# STM32H723xx register map
File version: 1.0
Registers are 32-bit, read-write, reset 0x0 unless marked. A register's access mark holds for its fields unless they carry their own. Offsets are from the block's base; [hi:lo] are bit positions; {n}, {i} and the like mark numbered series; 'fields as' and 'values as' point back to an identical list.

## FMC_Bank1E_R — Flexible Memory Controller Bank1E
Base 0x52004104
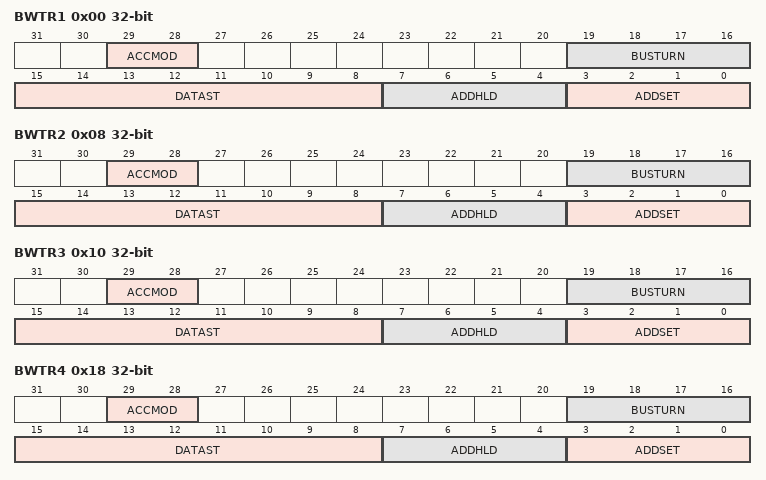
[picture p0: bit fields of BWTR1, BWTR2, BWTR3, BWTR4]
0x00 BWTR1 — NOR/PSRAM write timing registers
  [29:28] ACCMOD — ACCMOD[1:0] bits (Access mode)
  [19:16] BUSTURN — BUSTURN[3:0] bits (Bus turnaround phase duration)
  [15:8] DATAST — DATAST [3:0] bits (Data-phase duration)
  [7:4] ADDHLD — ADDHLD[3:0] bits (Address-hold phase duration)
  [3:0] ADDSET — ADDSET[3:0] bits (Address setup phase duration)
0x08 BWTR2 — NOR/PSRAM write timing registers
  fields as BWTR1
0x10 BWTR3 — NOR/PSRAM write timing registers
  fields as BWTR1
0x18 BWTR4 — NOR/PSRAM write timing registers
  fields as BWTR1

## FMC_Bank5_6_R — Flexible Memory Controller Bank5 and 6
Base 0x52004140
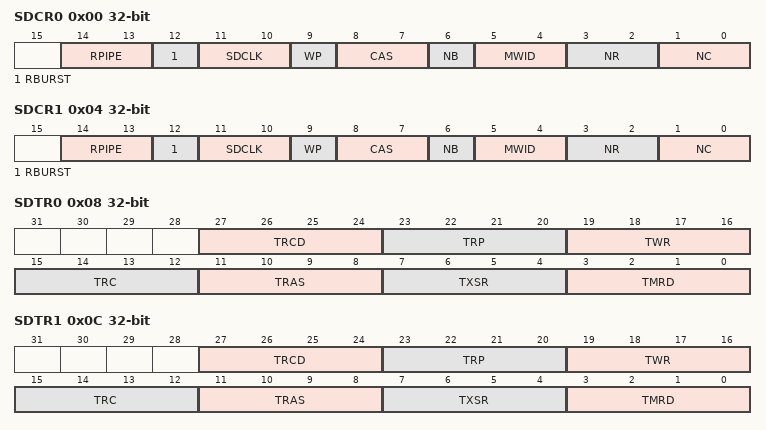
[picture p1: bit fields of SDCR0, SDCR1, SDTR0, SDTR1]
0x00 SDCR0 — SDRAM Control registers
  [14:13] RPIPE — Write protection
  [12] RBURST — Read burst
  [11:10] SDCLK — SDRAM clock configuration
  [9] WP — Write protection
  [8:7] CAS — CAS[1:0] bits (CAS latency)
  [6] NB — Number of internal bank
  [5:4] MWID — NR[1:0] bits (Number of row bits)
  [3:2] NR — NR[1:0] bits (Number of row bits)
  [1:0] NC — NC[1:0] bits (Number of column bits)
0x04 SDCR1 — SDRAM Control registers
  fields as SDCR0
0x08 SDTR0 — SDRAM Timing registers
  [27:24] TRCD — TRP[2:0] bits (Row to column delay)
  [23:20] TRP — TRP[2:0] bits (Row precharge delay)
  [19:16] TWR — TRC[2:0] bits (Write recovery delay)
  [15:12] TRC — TRC[2:0] bits (Row cycle delay)
  [11:8] TRAS — TRAS[3:0] bits (Self refresh time)
  [7:4] TXSR — TXSR[3:0] bits (Exit self refresh)
  [3:0] TMRD — TMRD[3:0] bits (Load mode register to active)
0x0C SDTR1 — SDRAM Timing registers
  fields as SDTR0
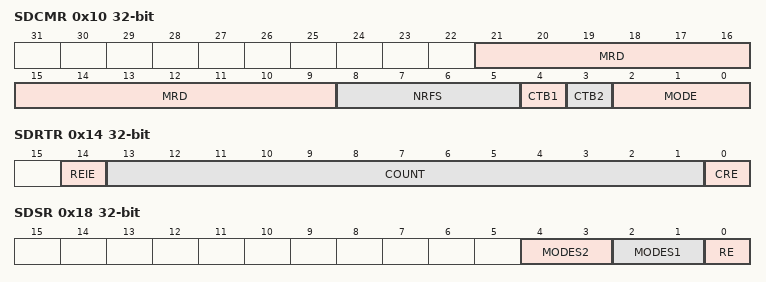
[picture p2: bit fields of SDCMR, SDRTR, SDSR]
0x10 SDCMR — SDRAM Command Mode register
  [21:9] MRD — MRD[12:0] bits (Mode register definition)
  [8:5] NRFS — NRFS[3:0] bits (Number of auto-refresh)
  [4] CTB1 — Command target 1
  [3] CTB2 — Command target 2
  [2:0] MODE — MODE[2:0] bits (Command mode)
0x14 SDRTR — SDRAM Refresh Timer register
  [14] REIE — RES interrupt enable
  [13:1] COUNT — COUNT[12:0] bits (Refresh timer count)
  [0] CRE — Clear refresh error flag
0x18 SDSR — SDRAM Status register
  [4:3] MODES2 — MODES2[1:0]bits (Status mode for bank 2)
  [2:1] MODES1 — MODES1[1:0]bits (Status mode for bank 1)
  [0] RE — Refresh error flag

## OCTOSPIM — OCTO Serial Peripheral Interface IO Manager
Base 0x5200B400
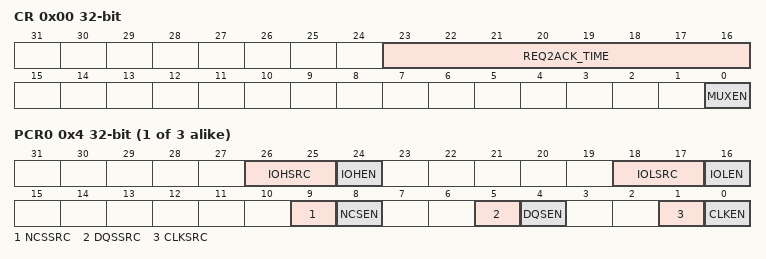
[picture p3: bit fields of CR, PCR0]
0x00 CR — OCTOSPI IO Manager Control register
  [23:16] REQ2ACK_TIME — REQ to ACK time
  [0] MUXEN — Multiplexed mode enable
{0x4+4i} PCR{i} (i=0..2) — OCTOSPI IO Manager Port[1:3] Configuration register
  [26:25] IOHSRC — IO[7:4] Source for Port n
  [24] IOHEN — IO[7:4] Enable for Port n
  [18:17] IOLSRC — IO[3:0] Source for Port n
  [16] IOLEN — IO[3:0] Enable for Port n
  [9] NCSSRC — nCS Source for Port n
  [8] NCSEN — nCS Enable for Port n
  [5] DQSSRC — DQS Source for Port n
  [4] DQSEN — DQS Enable for Port n
  [1] CLKSRC — CLK/CLKn Source for Port n
  [0] CLKEN — CLK/CLKn Enable for Port n

## COMP12 — Comparator
Base 0x58003800
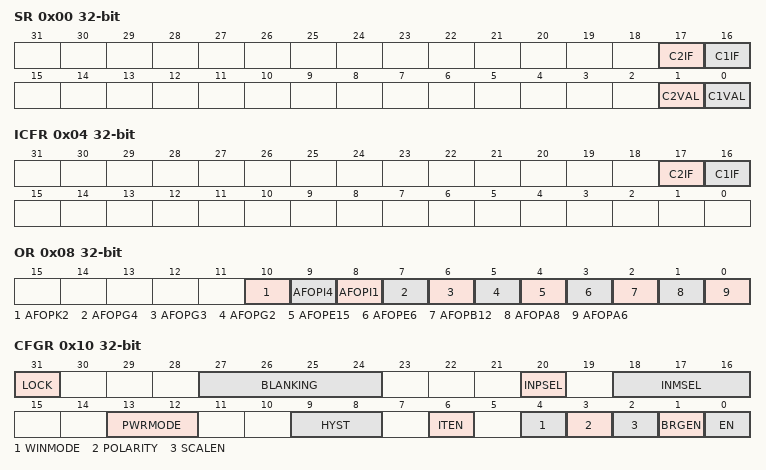
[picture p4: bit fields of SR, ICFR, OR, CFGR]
0x00 SR — Comparator status register
  [17] C2IF, [16] C1IF, [1] C2VAL, [0] C1VAL
0x04 ICFR — Comparator interrupt clear flag register
  [17] C2IF, [16] C1IF
0x08 OR — Comparator option register
  [10] AFOPK2, [9] AFOPI4, [8] AFOPI1, [7] AFOPG4, [6] AFOPG3, [5] AFOPG2, [4] AFOPE15, [3] AFOPE6, [2] AFOPB12, [1] AFOPA8, [0] AFOPA6
0x10 CFGR — COMP control and status register, used for bits common to several COMP instances
  [31] LOCK — COMPx Lock Bit
  [27:24] BLANKING — COMPx blanking source selection bits
    0=NONE (Comparator output without blanking); 1=TIM1_OC5 (Comparator output blanking source TIM1 OC5 (common to all COMP instances: COMP1, COMP2)); 2=TIM2_OC3 (Comparator output blanking source TIM2 OC3 (common to all COMP instances: COMP1, COMP2)); 3=TIM3_OC3 (Comparator output blanking source TIM3 OC3 (common to all COMP instances: COMP1, COMP2)); 4=TIM3_OC4 (Comparator output blanking source TIM3 OC4 (common to all COMP instances: COMP1, COMP2)); 5=TIM8_OC5 (Comparator output blanking source TIM8 OC5 (common to all COMP instances: COMP1, COMP2)); 6=TIM15_OC1 (Comparator output blanking source TIM15 OC1 (common to all COMP instances: COMP1, COMP2))
  [20] INPSEL — COMPx input plus selection bit
  [18:16] INMSEL — COMPx input minus selection bit
  [13:12] PWRMODE — COMPx Power Mode of the comparator
    0=HIGHSPEED (COMP power mode to high speed); 1=MEDIUMSPEED (COMP power mode to medium speed); 3=ULTRALOWPOWER (COMP power mode to ultra-low power)
  [9:8] HYST — COMPx hysteresis selection bits
    0=NONE (No hysteresis); 1=LOW (Hysteresis level low); 2=MEDIUM (Hysteresis level medium); 3=HIGH (Hysteresis level high)
  [6] ITEN — COMPx interrupt enable
  [4] WINMODE — COMPx Windows mode selection bit
    0=DISABLE (Window mode disable: Comparators 1 and 2 are independent); 1=COMP1_INPUT_PLUS_COMMON (Window mode enable: Comparators instances pair COMP1 and COMP2 have their input plus connected together. The common input is COMP1 input plus (COMP2 input plus is no more accessible).)
  [3] POLARITY — COMPx polarity selection bit
    0=NONINVERTED (COMP output polarity is not inverted: comparator output is high when the plus (non-inverting) input is at a higher voltage than the minus (inverting) input); 1=INVERTED (COMP output polarity is inverted: comparator output is low when the plus (non-inverting) input is at a lower voltage than the minus (inverting) input)
  [2] SCALEN — COMPx Voltage scaler enable bit
  [1] BRGEN — COMPx Scaler bridge enable
  [0] EN — COMPx enable bit
